# MDR1206AFI register map
Vendor: Milandr; File version: 1.0
CPU: BM-310S0, little endian
Registers are 32-bit, read-write, reset 0x0 unless marked. A register's access mark holds for its fields unless they carry their own. Offsets are from the block's base; lines under a group give offsets from that group; [hi:lo] are bit positions; {n}, {i} and the like mark numbered series; 'fields as' and 'values as' point back to an identical list; <NAME> marks a mode.

## Memory map
0x02000000 CLINT blocks up to offset 0xC000 — Сore Local Interruptor
0x0D000000 CLIC size 0x8000 — Core Local Interrupt Controller
0x50000000 SSP1 size 0x1000 — SSP1 Interface
0x50008000 UART1 size 0x1000 — UART1 Controller
0x50010000 UART2 size 0x1000 — UART2 Controller
0x50018000 FLASH_CNTRL size 0x1000 — FLASH Memory Controller
0x50020000 RST_CLK size 0x1000 — RST_CLK description
0x50028000 DMA size 0x1000 — DMA description
0x50030000 I2C size 0x1000 — I2C description
0x50038000 UART3 size 0x1000 — UART3 Controller
0x50040000 ADC size 0x1000 — ADC description
0x50048000 WWDG size 0x1000 — WWDG description
0x50050000 IWDG size 0x1000 — IWDG description
0x50058000 POWER size 0x1000 — POWER description
0x50060000 BKP size 0x1000 — BKP description
0x50068000 ADCUI size 0x1000 — ADCUI description
0x50070000 TIMER1 size 0x1000 — TIMER1 description
0x50078000 TIMER2 size 0x1000 — TIMER2 description
0x50080000 PORTA size 0x1000 — PORTA description
0x50088000 PORTB size 0x1000 — PORTB description
0x50090000 PORTC size 0x1000 — PORTC description
0x50098000 CRC size 0x1000 — CRC description
0x500B8000 RANDOM size 0x1000 — RANDOM description
0x500C0000 USART size 0x1000 — USART description
0x500C8000 SSP2 size 0x1000 — SSP2 Interface
0x500D0000 SSP3 size 0x1000 — SSP3 Interface
0x500D8000 TIMER3 size 0x1000 — TIMER3 description
0x500E0000 TIMER4 size 0x1000 — TIMER4 description
0x500E8000 UART4 size 0x1000 — UART4 Controller
0x500F0000 PORTD size 0x1000 — PORTD description

## Interrupts
0 DMA_IRQ (DMA)
1 UART1_IRQ (UART1)
2 UART2_IRQ (UART2)
3 SSP1_IRQ (SSP1)
4 POWER_IRQ (POWER)
5 WWDG_IRQ (WWDG)
6 TIMER1_IRQ (TIMER1)
7 TIMER2_IRQ (TIMER2)
8 ADC_IRQ (ADC)
9 I2C_IRQ (I2C)
10 BKP_IRQ (BKP)
11 EXT_INT1_IRQ (PORTA)
12 EXT_INT2_IRQ (PORTB)
13 EXT_INT3_IRQ (PORTC)
14 ADCUI_F03_IRQn (ADCUI)
15 ADCUI_F1_IRQn (ADCUI)
16 ADCUI_F2_IRQn (ADCUI)
21 RANDOM_IRQ (RANDOM)
22 USART_IRQ (USART)
23 UART3_IRQ (UART3)
24 SSP2_IRQ (SSP2)
25 SSP3_IRQ (SSP3)
26 TIMER3_IRQ (TIMER3)
27 TIMER4_IRQ (TIMER4)
28 UART4_IRQ (UART4)

## CLINT — Сore Local Interruptor
Base 0x02000000
0x00 CTMSIP — Software Interrupt Request/Clear Register
  [0] msip — Waiting for software interrupt
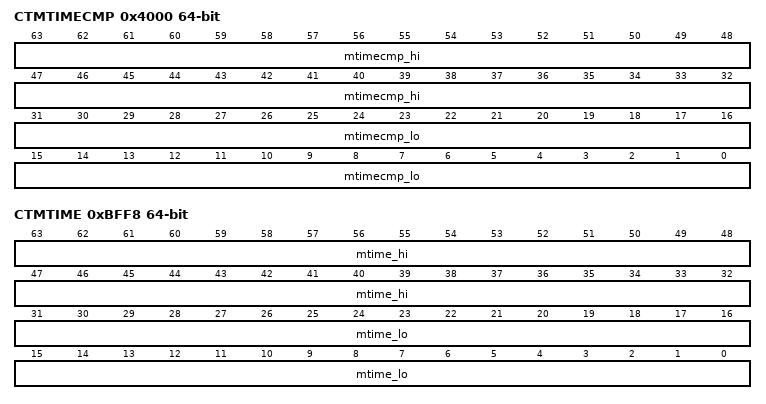
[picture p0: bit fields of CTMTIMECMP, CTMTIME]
0x4000 CTMTIMECMP 64-bit — Machine Timer Comparison Register
  [63:32] mtimecmp_hi — High part of the value of the comparison register
  [31:0] mtimecmp_lo — Low part of the value of the comparison register
0xBFF8 CTMTIME 64-bit — Machine Timer Value Register
  [63:32] mtime_hi — High part of the timer value
  [31:0] mtime_lo — Low part of the timer value

## CLIC — Core Local Interrupt Controller
Base 0x0D000000
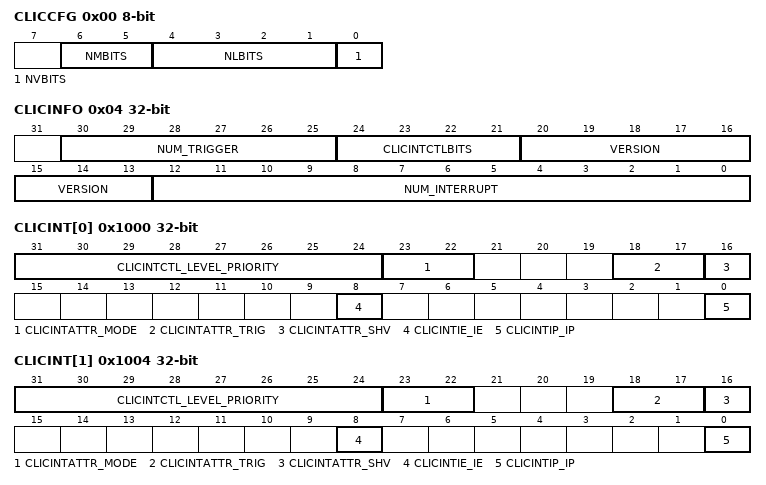
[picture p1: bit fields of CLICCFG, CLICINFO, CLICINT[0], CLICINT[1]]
0x00 CLICCFG 8-bit — CLICCFG description
  [6:5] NMBITS — NMBITS description
  [4:1] NLBITS — NLBITS description
  [0] NVBITS ro — NVBITS description
0x04 CLICINFO ro — CLICINFO description
  [30:25] NUM_TRIGGER — NUM_TRIGGER description
  [24:21] CLICINTCTLBITS — CLICINTCTLBITS description
  [20:13] VERSION — version description
  [12:0] NUM_INTERRUPT — NUM_INTERRUPT description
0x1000 CLICINT[0] — CLICINT[0]_USIP description
  [31:24] CLICINTCTL_LEVEL_PRIORITY — LEVEL_PRIORITY description
  [23:22] CLICINTATTR_MODE — MODE description
  [18:17] CLICINTATTR_TRIG — TRIG description
  [16] CLICINTATTR_SHV — SHV description
  [8] CLICINTIE_IE — IE description
  [0] CLICINTIP_IP — IP description
0x1004 CLICINT[1] — CLICINT[1] description
  fields as CLICINT[0]
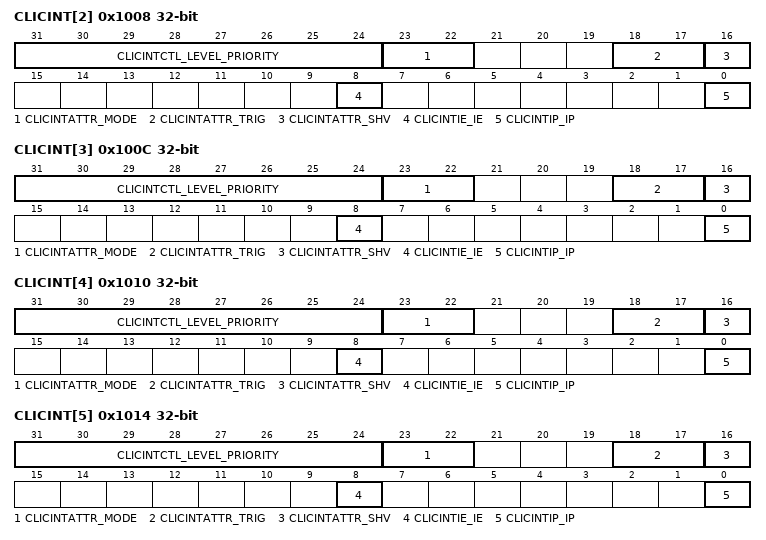
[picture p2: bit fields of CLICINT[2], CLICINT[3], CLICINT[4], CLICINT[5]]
0x1008 CLICINT[2] — CLICINT[2] description
  fields as CLICINT[0]
0x100C CLICINT[3] — CLICINT[3]_MSIP description
  fields as CLICINT[0]
0x1010 CLICINT[4] — CLICINT[4]_UTIP description
  fields as CLICINT[0]
0x1014 CLICINT[5] — CLICINT[5] description
  fields as CLICINT[0]
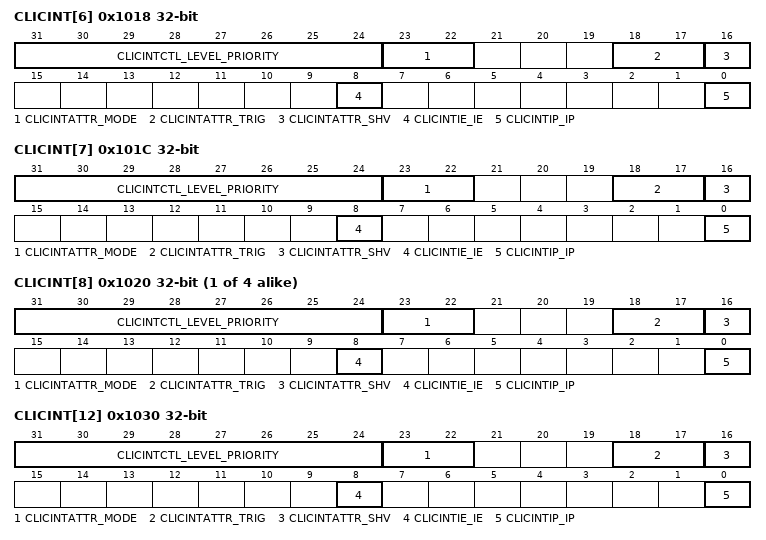
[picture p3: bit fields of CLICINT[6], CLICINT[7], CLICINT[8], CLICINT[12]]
0x1018 CLICINT[6] — CLICINT[6] description
  fields as CLICINT[0]
0x101C CLICINT[7] — CLICINT[7]_MTIP description
  fields as CLICINT[0]
{0x1000+4i} CLICINT[{i}] (i=8..11) — CLICINT[{i}] description
  fields as CLICINT[0]
0x1030 CLICINT[12] — CLICINT[12]_CSIP description
  fields as CLICINT[0]
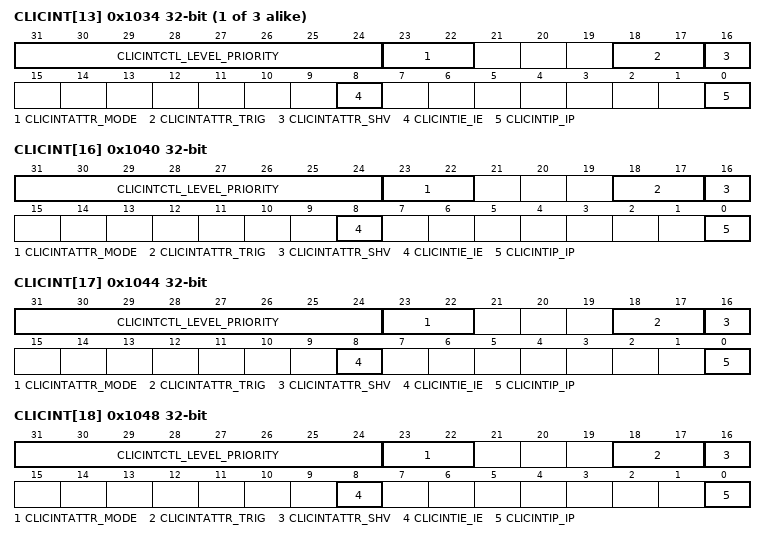
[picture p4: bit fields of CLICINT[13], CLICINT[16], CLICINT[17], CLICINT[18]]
{0x1000+4i} CLICINT[{i}] (i=13..15) — CLICINT[{i}] description
  fields as CLICINT[0]
0x1040 CLICINT[16] — CLICINT[16]_DMA description
  fields as CLICINT[0]
0x1044 CLICINT[17] — CLICINT[17]_UART1 description
  fields as CLICINT[0]
0x1048 CLICINT[18] — CLICINT[18]_UART2 description
  fields as CLICINT[0]
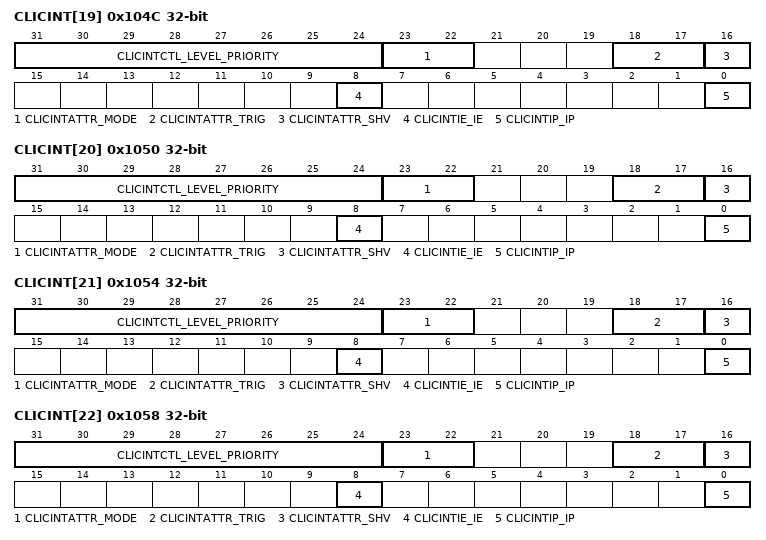
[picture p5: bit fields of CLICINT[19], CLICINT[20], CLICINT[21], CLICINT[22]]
0x104C CLICINT[19] — CLICINT[19]_SSP1 description
  fields as CLICINT[0]
0x1050 CLICINT[20] — CLICINT[20]_POWER description
  fields as CLICINT[0]
0x1054 CLICINT[21] — CLICINT[21]_WWDG description
  fields as CLICINT[0]
0x1058 CLICINT[22] — CLICINT[22]_TIMER1 description
  fields as CLICINT[0]
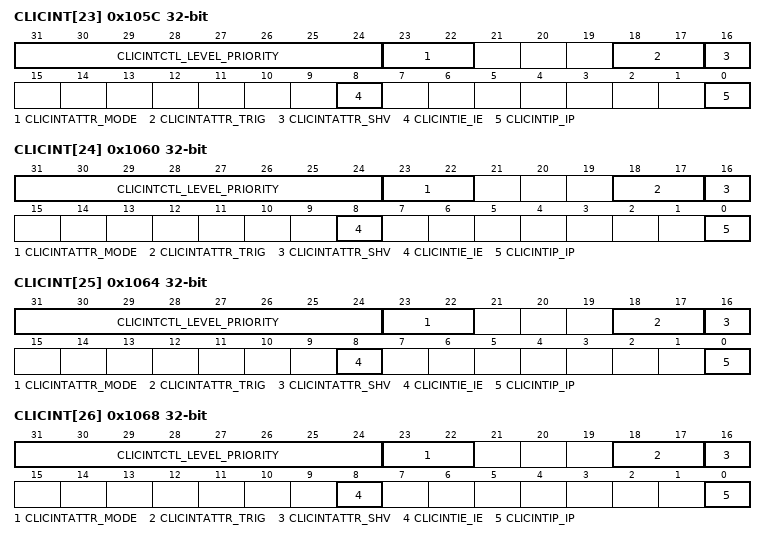
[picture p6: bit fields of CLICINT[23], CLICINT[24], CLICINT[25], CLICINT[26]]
0x105C CLICINT[23] — CLICINT[23]_TIMER2 description
  fields as CLICINT[0]
0x1060 CLICINT[24] — CLICINT[24]_ADC description
  fields as CLICINT[0]
0x1064 CLICINT[25] — CLICINT[25]_I2C description
  fields as CLICINT[0]
0x1068 CLICINT[26] — CLICINT[26]_BKP description
  fields as CLICINT[0]
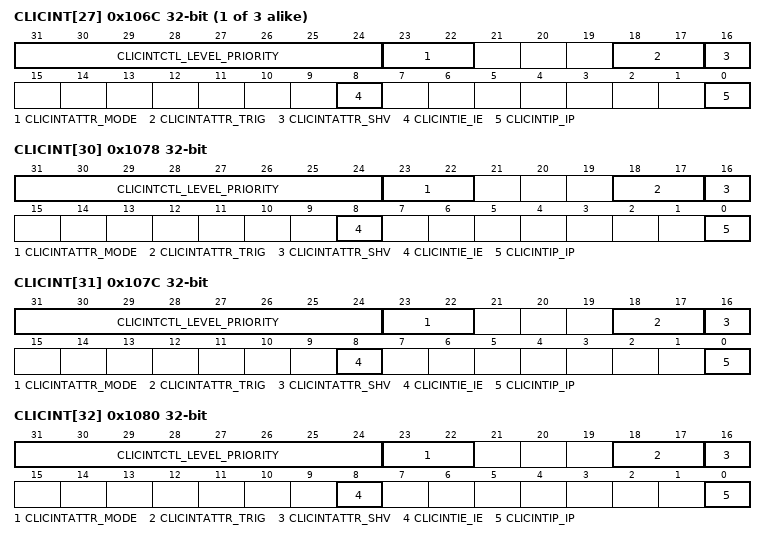
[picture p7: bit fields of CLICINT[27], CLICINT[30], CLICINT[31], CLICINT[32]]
{0x1000+4i} CLICINT[{i}] (i=27..29) — CLICINT[{i}]_EXT_INT{i-27} description
  fields as CLICINT[0]
0x1078 CLICINT[30] — CLICINT[30]_ADCUI_F03 description
  fields as CLICINT[0]
0x107C CLICINT[31] — CLICINT[31]_ADCUI_F1 description
  fields as CLICINT[0]
0x1080 CLICINT[32] — CLICINT[32]_ADCUI_F2 description
  fields as CLICINT[0]
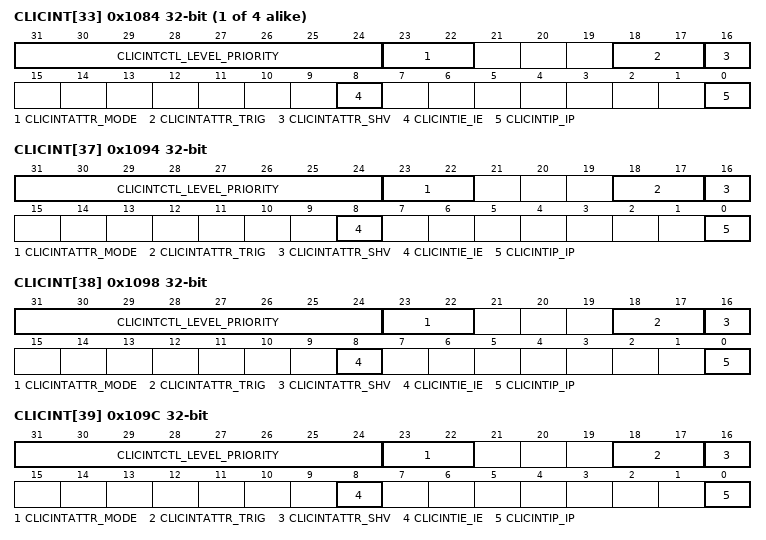
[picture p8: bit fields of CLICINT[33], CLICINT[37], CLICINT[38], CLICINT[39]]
{0x1000+4i} CLICINT[{i}] (i=33..36) — CLICINT[{i}] description
  fields as CLICINT[0]
0x1094 CLICINT[37] — CLICINT[37]_RANDOM description
  fields as CLICINT[0]
0x1098 CLICINT[38] — CLICINT[38]_ISO7816 description
  fields as CLICINT[0]
0x109C CLICINT[39] — CLICINT[39]_UART3 description
  fields as CLICINT[0]
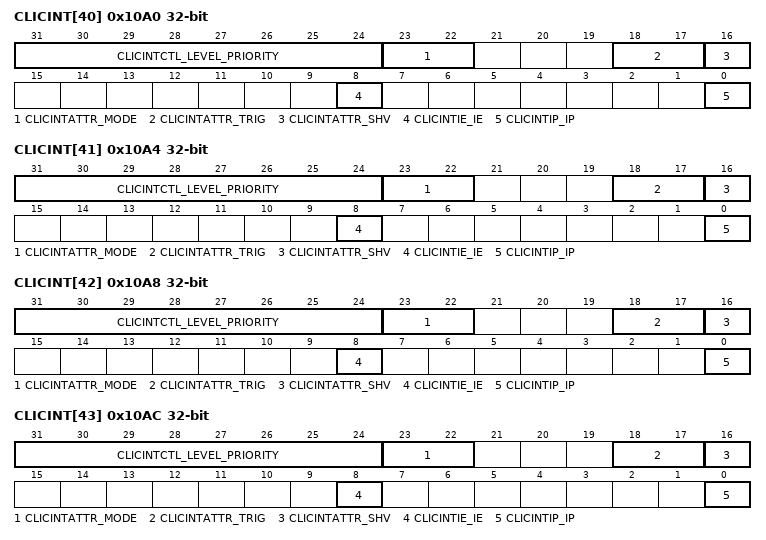
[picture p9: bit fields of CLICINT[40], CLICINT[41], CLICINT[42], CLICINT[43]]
0x10A0 CLICINT[40] — CLICINT[40]_SSP2 description
  fields as CLICINT[0]
0x10A4 CLICINT[41] — CLICINT[41]_SSP3 description
  fields as CLICINT[0]
0x10A8 CLICINT[42] — CLICINT[42]_TIMER3 description
  fields as CLICINT[0]
0x10AC CLICINT[43] — CLICINT[43]_TIMER4 description
  fields as CLICINT[0]
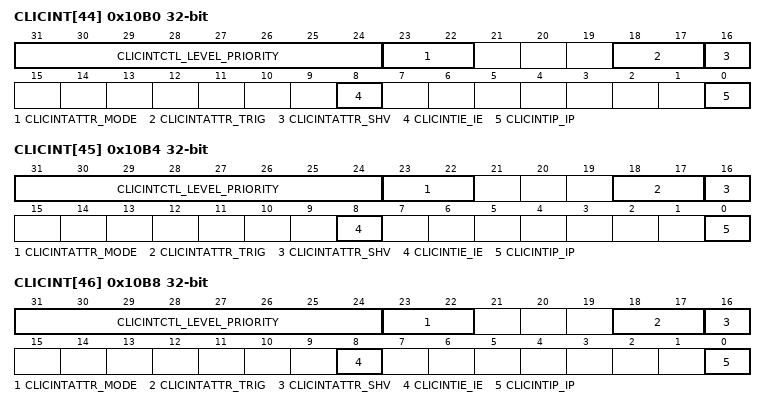
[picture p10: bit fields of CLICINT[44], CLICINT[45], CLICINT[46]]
0x10B0 CLICINT[44] — CLICINT[44]_UART4 description
  fields as CLICINT[0]
0x10B4 CLICINT[45] — CLICINT[45] description
  fields as CLICINT[0]
0x10B8 CLICINT[46] — CLICINT[46] description
  fields as CLICINT[0]
